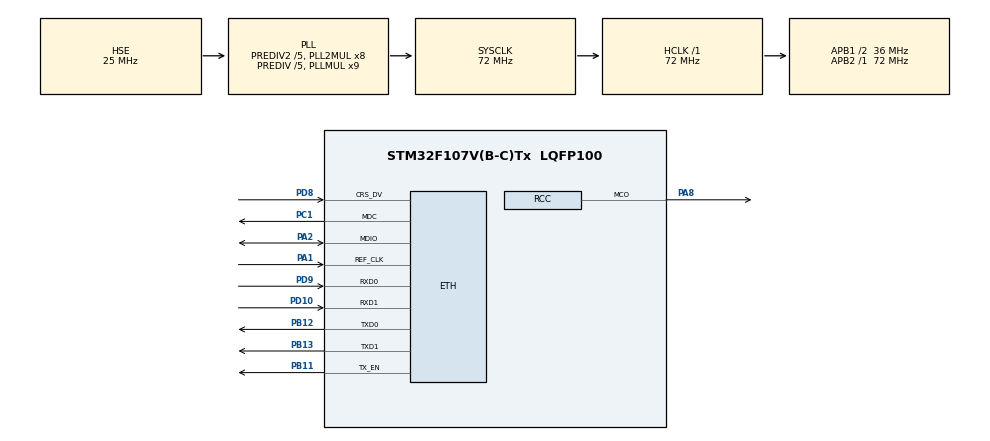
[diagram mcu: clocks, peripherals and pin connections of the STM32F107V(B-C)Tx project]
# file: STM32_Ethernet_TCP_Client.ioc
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ETH.MediaInterface=ETH_MEDIA_INTERFACE_RMII
ETH.PHY_Name_RMII=DP83848_PHY_ADDRESS
LWIP.GATEWAY_ADDRESS=192.168.031.001
LWIP.IP_ADDRESS=192.168.031.201
LWIP.LWIP_DHCP=0
LWIP.NETMASK_ADDRESS=255.255.255.000
LWIP.Version=v2.0.3_Cube
Mcu.Family=STM32F1
Mcu.Name=STM32F107V(B-C)Tx
Mcu.Package=LQFP100
NVIC.ETH_IRQn=true\:0\:0\:false\:false\:true\:true\:true\:true
NVIC.PriorityGroup=NVIC_PRIORITYGROUP_4
NVIC.TIM3_IRQn=true\:0\:0\:false\:false\:true\:true\:true\:true
OSC_IN.Mode=HSE-External-Oscillator
OSC_IN.Signal=RCC_OSC_IN
OSC_OUT.Mode=HSE-External-Oscillator
OSC_OUT.Signal=RCC_OSC_OUT
PA1.Mode=RMII
PA1.Signal=ETH_REF_CLK
PA13.Mode=Serial_Wire
PA13.Signal=SYS_JTMS-SWDIO
PA14.Mode=Serial_Wire
PA14.Signal=SYS_JTCK-SWCLK
PA2.Mode=RMII
PA2.Signal=ETH_MDIO
PA8.GPIO_Speed=GPIO_SPEED_FREQ_MEDIUM
PA8.Mode=Clock-out
PA8.Signal=RCC_MCO
PB11.Mode=RMII
PB11.Signal=ETH_TX_EN
PB12.Mode=RMII
PB12.Signal=ETH_TXD0
PB13.Mode=RMII
PB13.Signal=ETH_TXD1
PC1.Mode=RMII
PC1.Signal=ETH_MDC
PD10.Mode=RMII
PD10.Signal=ETH_RXD1
PD8.Mode=RMII
PD8.Signal=ETH_CRS_DV
PD9.Mode=RMII
PD9.Signal=ETH_RXD0
ProjectManager.HeapSize=0x200
ProjectManager.StackSize=0x400
ProjectManager.TargetToolchain=STM32CubeIDE
RCC.AHBFreq_Value=72000000
RCC.APB1CLKDivider=RCC_HCLK_DIV2
RCC.APB1Freq_Value=36000000
RCC.APB1TimFreq_Value=72000000
RCC.APB2Freq_Value=72000000
RCC.APB2TimFreq_Value=72000000
RCC.HCLKFreq_Value=72000000
RCC.HSEDivPLL=RCC_HSE_PREDIV_DIV5
RCC.HSE_VALUE=25000000
RCC.PLL3Mul=RCC_PLLI2S_MUL10
RCC.PLLMUL=RCC_PLL_MUL9
RCC.PLLSourceVirtual=RCC_PLLSOURCE_HSE
RCC.Prediv1Source=RCC_PREDIV1_SOURCE_PLL2
RCC.Prediv2=RCC_HSE_PREDIV2_DIV5
RCC.RCC_MCOSource=RCC_MCO1SOURCE_PLL3CLK
RCC.SYSCLKFreq_VALUE=72000000
RCC.SYSCLKSource=RCC_SYSCLKSOURCE_PLLCLK
RCC.USBFreq_Value=48000000
TIM3.Period=9999
TIM3.Prescaler=7199
VP_LWIP_VS_Enabled.Mode=Enabled
VP_TIM3_VS_ClockSourceINT.Mode=Internal
board=custom

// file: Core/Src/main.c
/* USER CODE BEGIN Header */
/**
  ******************************************************************************
  * @file           : main.c
  * @brief          : Main program body
  ******************************************************************************
  * @attention
  *
  * Copyright (c) 2024 STMicroelectronics.
  * All rights reserved.
  *
  * This software is licensed under terms that can be found in the LICENSE file
  * in the root directory of this software component.
  * If no LICENSE file comes with this software, it is provided AS-IS.
  *
  ******************************************************************************
  */
/* USER CODE END Header */
#include "main.h"
#include "lwip.h"

/* USER CODE BEGIN Includes */
#include "tcpClientRAW.h"
/* USER CODE END Includes */

TIM_HandleTypeDef htim3;

void SystemClock_Config(void);
static void MX_GPIO_Init(void);
static void MX_TIM3_Init(void);

/* USER CODE BEGIN 0 */
extern struct netif gnetif;
/* USER CODE END 0 */

int main(void)
{

  /* MCU Configuration--------------------------------------------------------*/

  /* Reset of all peripherals, Initializes the Flash interface and the Systick. */
  HAL_Init();

  /* Configure the system clock */
  SystemClock_Config();

  /* Initialize all configured peripherals */
  MX_GPIO_Init();
  MX_LWIP_Init();
  MX_TIM3_Init();
  /* USER CODE BEGIN 2 */
  HAL_TIM_Base_Start_IT(&htim3);

    tcp_client_init();
  /* USER CODE END 2 */

  /* Infinite loop */
  /* USER CODE BEGIN WHILE */
  while (1)
  {
	ethernetif_input(&gnetif);
	sys_check_timeouts();
    /* USER CODE END WHILE */

  }
}

void SystemClock_Config(void)
{
  RCC_OscInitTypeDef RCC_OscInitStruct = {0};
  RCC_ClkInitTypeDef RCC_ClkInitStruct = {0};

  /** Initializes the RCC Oscillators according to the specified parameters
  * in the RCC_OscInitTypeDef structure.
  */
  RCC_OscInitStruct.OscillatorType = RCC_OSCILLATORTYPE_HSE;
  RCC_OscInitStruct.HSEState = RCC_HSE_ON;
  RCC_OscInitStruct.HSEPredivValue = RCC_HSE_PREDIV_DIV5;
  RCC_OscInitStruct.HSIState = RCC_HSI_ON;
  RCC_OscInitStruct.Prediv1Source = RCC_PREDIV1_SOURCE_PLL2;
  RCC_OscInitStruct.PLL.PLLState = RCC_PLL_ON;
  RCC_OscInitStruct.PLL.PLLSource = RCC_PLLSOURCE_HSE;
  RCC_OscInitStruct.PLL.PLLMUL = RCC_PLL_MUL9;
  RCC_OscInitStruct.PLL2.PLL2State = RCC_PLL2_ON;
  RCC_OscInitStruct.PLL2.PLL2MUL = RCC_PLL2_MUL8;
  RCC_OscInitStruct.PLL2.HSEPrediv2Value = RCC_HSE_PREDIV2_DIV5;
  if (HAL_RCC_OscConfig(&RCC_OscInitStruct) != HAL_OK)
  {
    Error_Handler();
  }

  /** Initializes the CPU, AHB and APB buses clocks
  */
  RCC_ClkInitStruct.ClockType = RCC_CLOCKTYPE_HCLK|RCC_CLOCKTYPE_SYSCLK
                              |RCC_CLOCKTYPE_PCLK1|RCC_CLOCKTYPE_PCLK2;
  RCC_ClkInitStruct.SYSCLKSource = RCC_SYSCLKSOURCE_PLLCLK;
  RCC_ClkInitStruct.AHBCLKDivider = RCC_SYSCLK_DIV1;
  RCC_ClkInitStruct.APB1CLKDivider = RCC_HCLK_DIV2;
  RCC_ClkInitStruct.APB2CLKDivider = RCC_HCLK_DIV1;

  if (HAL_RCC_ClockConfig(&RCC_ClkInitStruct, FLASH_LATENCY_2) != HAL_OK)
  {
    Error_Handler();
  }
  HAL_RCC_MCOConfig(RCC_MCO, RCC_MCO1SOURCE_PLL3CLK, RCC_MCODIV_1);

  /** Configure the Systick interrupt time
  */
  __HAL_RCC_HSE_PREDIV2_CONFIG(RCC_HSE_PREDIV2_DIV5);

  /** Configure the Systick interrupt time
  */
  __HAL_RCC_PLLI2S_CONFIG(RCC_PLLI2S_MUL10);

  /** Configure the Systick interrupt time
  */
  __HAL_RCC_PLLI2S_ENABLE();
}

static void MX_TIM3_Init(void)
{

  TIM_ClockConfigTypeDef sClockSourceConfig = {0};
  TIM_MasterConfigTypeDef sMasterConfig = {0};

  htim3.Instance = TIM3;
  htim3.Init.Prescaler = 7199;
  htim3.Init.CounterMode = TIM_COUNTERMODE_UP;
  htim3.Init.Period = 9999;
  htim3.Init.ClockDivision = TIM_CLOCKDIVISION_DIV1;
  htim3.Init.AutoReloadPreload = TIM_AUTORELOAD_PRELOAD_DISABLE;
  if (HAL_TIM_Base_Init(&htim3) != HAL_OK)
  {
    Error_Handler();
  }
  sClockSourceConfig.ClockSource = TIM_CLOCKSOURCE_INTERNAL;
  if (HAL_TIM_ConfigClockSource(&htim3, &sClockSourceConfig) != HAL_OK)
  {
    Error_Handler();
  }
  sMasterConfig.MasterOutputTrigger = TIM_TRGO_RESET;
  sMasterConfig.MasterSlaveMode = TIM_MASTERSLAVEMODE_DISABLE;
  if (HAL_TIMEx_MasterConfigSynchronization(&htim3, &sMasterConfig) != HAL_OK)
  {
    Error_Handler();
  }

}

static void MX_GPIO_Init(void)
{
  GPIO_InitTypeDef GPIO_InitStruct = {0};

  /* GPIO Ports Clock Enable */
  __HAL_RCC_GPIOC_CLK_ENABLE();
  __HAL_RCC_GPIOA_CLK_ENABLE();
  __HAL_RCC_GPIOB_CLK_ENABLE();
  __HAL_RCC_GPIOD_CLK_ENABLE();

  /*Configure GPIO pin : PA8 */
  GPIO_InitStruct.Pin = GPIO_PIN_8;
  GPIO_InitStruct.Mode = GPIO_MODE_AF_PP;
  GPIO_InitStruct.Speed = GPIO_SPEED_FREQ_MEDIUM;
  HAL_GPIO_Init(GPIOA, &GPIO_InitStruct);

}

void Error_Handler(void)
{
  __disable_irq();
  while (1)
  {
  }
}
